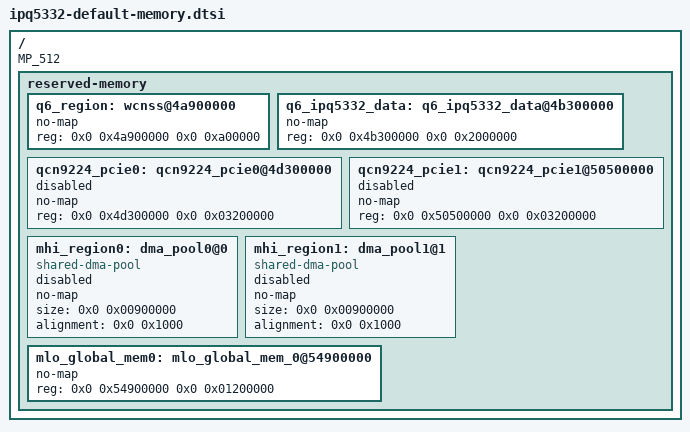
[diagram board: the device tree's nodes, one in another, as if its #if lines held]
// SPDX-License-Identifier: (GPL-2.0+ OR BSD-3-Clause)
/*
 * IPQ5332 Memory device tree source
 *
 * Copyright (c) 2022-2023 Qualcomm Innovation Center, Inc. All rights reserved.
 */

/ {

	/*                Default Profile
	* +=========+==============+========================+
	* |        |              |                         |
	* | Region | Start Offset |          Size           |
	* |        |              |                         |
	* +--------+--------------+-------------------------+
	* |        |              |                         |
	* |        |              |                         |
	* | WLAN   |              |                         |
	* |   Q6   |  0x4A900000  |          35MB           |
	* |        |              |                         |
	* |        |              |                         |
	* +--------+--------------+-------------------------+
	* | M3 Dump|  0x4CC00000  |          1MB            |
	* +--------+--------------+-------------------------+
	* | WLAN   |              |                         |
	* | Q6 ETR |  0x4CD00000  |          1MB            |
	* | Region |              |                         |
	* +--------+--------------+-------------------------+
	* | caldb  |  0x4CE00000  |           5MB           |
	* +--------+--------------+-------------------------+
	* |  MLO   |  0x4DB00000  |          18MB           |
	* +--------+--------------+-------------------------+
	* |        |              |                         |
	* |QCN9224 |  0x4ED00000  |          50MB           |
	* |PCIE0   |              |                         |
	* |        |              |                         |
	* +--------+--------------+-------------------------+
	* |        |              |                         |
	* |QCN9224 |  0x51F00000  |          50MB           |
	* |PCIE1   |              |                         |
	* |        |              |                         |
	* +--------+--------------+-------------------------+
	* |        |              |                         |
	* |  MHI0  |    DYNAMIC   |          9MB            |
	* |        |              |                         |
	* +--------+--------------+-------------------------+
	* |        |              |                         |
	* |  MHI1  |    DYNAMIC   |          9MB            |
	* |        |              |                         |
	* +=================================================+
	* |                                                 |
	* |                                                 |
	* |                                                 |
	* |            Rest of memory for Linux             |
	* |                                                 |
	* |                                                 |
	* |                                                 |
	* +=================================================+
	*/

#if defined(__IPQ_MEM_PROFILE_512_MB__)
	MP_512;
#endif

	reserved-memory {
		#address-cells = <2>;
		#size-cells = <2>;
		ranges;

		q6_region: wcnss@4a900000 {
			no-map;
			reg = <0x0 0x4a900000 0x0 0xa00000>;
		};

		q6_ipq5332_data: q6_ipq5332_data@4b300000 {
			no-map;
			reg = <0x0 0x4b300000 0x0 0x2000000>;
		};

		qcn9224_pcie0: qcn9224_pcie0@4d300000 {
			no-map;
			reg = <0x0 0x4d300000 0x0 0x03200000>;
			status = "disabled";
		};

		qcn9224_pcie1: qcn9224_pcie1@50500000 {
			no-map;
			reg = <0x0 0x50500000 0x0 0x03200000>;
			status = "disabled";
		};

		mhi_region0: dma_pool0@0 {
			compatible = "shared-dma-pool";
			no-map;
			size = <0x0 0x00900000>;
			alignment = <0x0 0x1000>;
			status = "disabled";
		};

		mhi_region1: dma_pool1@1 {
			compatible = "shared-dma-pool";
			no-map;
			size = <0x0 0x00900000>;
			alignment = <0x0 0x1000>;
			status = "disabled";
		};

		mlo_global_mem0: mlo_global_mem_0@54900000 {
			no-map;
			reg = <0x0 0x54900000 0x0 0x01200000>;
		};
	};
};
